# cbass_CBASS_ISC_45820000h register map
Vendor: Texas Instruments
Registers are 32-bit, read-write, reset 0x0 unless marked. A register's access mark holds for its fields unless they carry their own. Offsets are as the file gives them; [hi:lo] are bit positions; {n}, {i} and the like mark numbered series; 'fields as' and 'values as' point back to an identical list.

## cbass_isc (part 2 of 2)
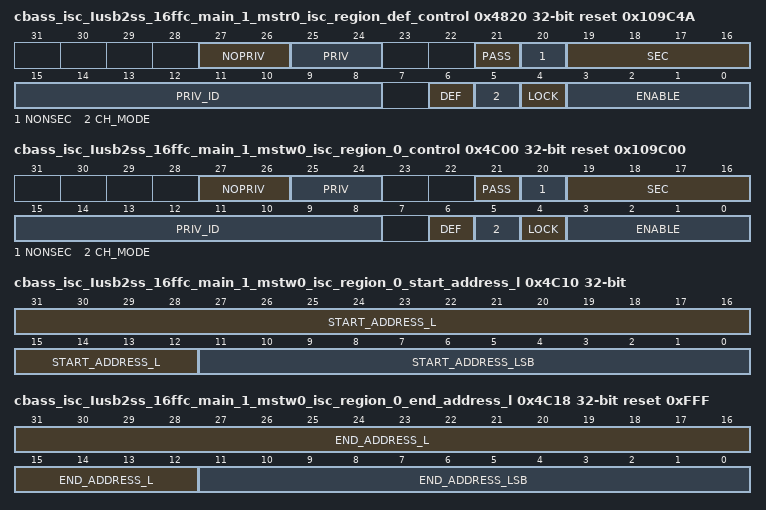
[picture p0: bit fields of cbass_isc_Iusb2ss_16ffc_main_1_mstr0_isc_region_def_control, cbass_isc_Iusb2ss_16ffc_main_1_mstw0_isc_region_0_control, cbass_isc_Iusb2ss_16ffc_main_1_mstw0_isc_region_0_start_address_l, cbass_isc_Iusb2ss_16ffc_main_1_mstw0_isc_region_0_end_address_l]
0x4820 cbass_isc_Iusb2ss_16ffc_main_1_mstr0_isc_region_def_control access not given reset 0x109C4A — The ISC Default Region Control Register defines the control fields for the master Iusb2ss_16ffc_main_1.mstr0 region 1 ISC.
  [27:26] NOPRIV rw — Clear output priv attribute. If each bit is set then the outgoing priv bit is cleared, else the bit is unchanged. Do not set both priv and nopriv for the same bit. Reset Source: domain_default_rst_mod_g_rst_n
  [25:24] PRIV rw — Set outgoing priv attribute. If each bit is set then the outgoing priv bit is set, else the bit is unchanged. Do not set both priv and nopriv for the same bit. Reset Source: domain_default_rst_mod_g_rst_n
  [21] PASS rw — No privID replacement. A value of 1 will pass through privid value. A value of 0 will replace privid with priv_id field value. Reset Source: domain_default_rst_mod_g_rst_n
  [20] NONSEC rw — Make outgoing non-secure. A value of 1 forces secure clear, others do nothing. Do not set both sec and nonsec. Reset Source: domain_default_rst_mod_g_rst_n
  [19:16] SEC rw — Make outgoing secure. A value of 0xA forces secure set, others do nothing. Do not set both sec and nonsec. Reset Source: domain_default_rst_mod_g_rst_n
  [15:8] PRIV_ID rw — Priv ID value to use if pass is 0. Reset Source: domain_default_rst_mod_g_rst_n
  [6] DEF ro — Default region indication. The default region is used when all other regions do not match. Reset Source: domain_default_rst_mod_g_rst_n
  [5] CH_MODE ro — Enable channel mode to match region to a chanid value. Otherwise use address mode to match region to an address range. Reset Source: domain_default_rst_mod_g_rst_n
  [4] LOCK — Lock region. Once set, the region values cannot be modified. Reset Source: domain_default_rst_mod_g_rst_n (access R/W1TS)
  [3:0] ENABLE ro — Enable region. A value of 0xA enables, others disable. Reset Source: domain_default_rst_mod_g_rst_n
0x4C00 cbass_isc_Iusb2ss_16ffc_main_1_mstw0_isc_region_0_control access not given reset 0x109C00 — The ISC Region 0 Control Register defines the control fields for the master Iusb2ss_16ffc_main_1.mstw0 region 0 ISC.
  [27:26] NOPRIV rw — Clear output priv attribute. If each bit is set then the outgoing priv bit is cleared. Reset Source: domain_default_rst_mod_g_rst_n
  [25:24] PRIV rw — Set outgoing priv attribute. If each bit is set then the outgoing priv bit is set. Reset Source: domain_default_rst_mod_g_rst_n
  [21] PASS rw — No privID replacement, pass through value. Reset Source: domain_default_rst_mod_g_rst_n
  [20] NONSEC rw — Make outgoing non-secure. Reset Source: domain_default_rst_mod_g_rst_n
  [19:16] SEC rw — Make outgoing secure. A value of 0xA enables, others disable. Reset Source: domain_default_rst_mod_g_rst_n
  [15:8] PRIV_ID rw — Priv ID. Reset Source: domain_default_rst_mod_g_rst_n
  [6] DEF ro — Default region indication. The default region is used when all other regions do not match. Reset Source: domain_default_rst_mod_g_rst_n
  [5] CH_MODE rw — Enable channel mode to match region to a chanid value. Otherwise use address mode to match region to an address range. Reset Source: domain_default_rst_mod_g_rst_n
  [4] LOCK — Lock region. Once set the region values cannot be modified. Reset Source: domain_default_rst_mod_g_rst_n (access R/W1TS)
  [3:0] ENABLE rw — Enable region. A value of 0xA enables, others disable. Reset Source: domain_default_rst_mod_g_rst_n
0x4C10 cbass_isc_Iusb2ss_16ffc_main_1_mstw0_isc_region_0_start_address_l — The ISC Region 0 Start Address Low Register defines the start address bits 31 to 0 for the master Iusb2ss_16ffc_main_1.mstw0 region 0 ISC.
  [31:12] START_ADDRESS_L — Start address bits 31 to 12. Reset Source: domain_default_rst_mod_g_rst_n
  [11:0] START_ADDRESS_LSB — Start address bits 11 to 0 must be 0 as address must be 4KB aligned in address mode. Can also be channel number in channel mode. Reset Source: domain_default_rst_mod_g_rst_n
0x4C14 cbass_isc_Iusb2ss_16ffc_main_1_mstw0_isc_region_0_start_address_h — The ISC Region 0 Start Address High Register defines the start address bits 47 to 32 for the master Iusb2ss_16ffc_main_1.mstw0 region 0 ISC.
  [15:0] START_ADDRESS_H — Start address bits 47 to 32. Reset Source: domain_default_rst_mod_g_rst_n
0x4C18 cbass_isc_Iusb2ss_16ffc_main_1_mstw0_isc_region_0_end_address_l access per field reset 0xFFF — The ISC Region 0 End Address Low Register defines the end included address bits 31 to 0 for the master Iusb2ss_16ffc_main_1.mstw0 region 0 ISC.
  [31:12] END_ADDRESS_L rw — End address bits 31 to 12 to include in the match. Reset Source: domain_default_rst_mod_g_rst_n
  [11:0] END_ADDRESS_LSB ro — End address bits 11 to 0 are forced to Fs as address must be 4KB aligned. Reset Source: domain_default_rst_mod_g_rst_n
0x4C1C cbass_isc_Iusb2ss_16ffc_main_1_mstw0_isc_region_0_end_address_h — The ISC Region 0 End Address High Register defines the end address bits 47 to 32 for the master Iusb2ss_16ffc_main_1.mstw0 region 0 ISC.
  [15:0] END_ADDRESS_H — End address bits 47 to 32. Reset Source: domain_default_rst_mod_g_rst_n
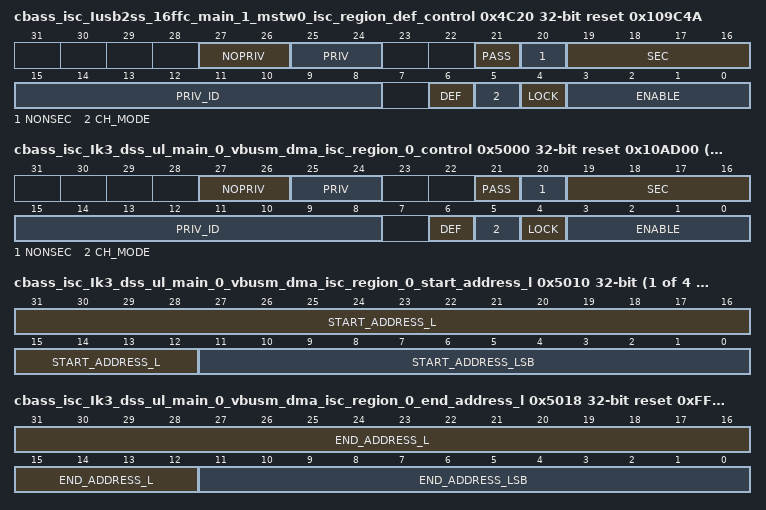
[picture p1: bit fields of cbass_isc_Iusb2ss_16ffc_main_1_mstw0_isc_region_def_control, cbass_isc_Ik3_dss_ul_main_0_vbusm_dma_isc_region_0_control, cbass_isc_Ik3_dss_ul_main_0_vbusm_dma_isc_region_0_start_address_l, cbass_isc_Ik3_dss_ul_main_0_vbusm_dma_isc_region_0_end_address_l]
0x4C20 cbass_isc_Iusb2ss_16ffc_main_1_mstw0_isc_region_def_control access not given reset 0x109C4A — The ISC Default Region Control Register defines the control fields for the master Iusb2ss_16ffc_main_1.mstw0 region 1 ISC.
  fields as cbass_isc_Iusb2ss_16ffc_main_1_mstr0_isc_region_def_control
{0x5000+0x20*i} cbass_isc_Ik3_dss_ul_main_0_vbusm_dma_isc_region_{i}_control access not given reset 0x10AD00 (i=0..3) — The ISC Region {i} Control Register defines the control fields for the master Ik3_dss_ul_main_0.vbusm_dma region {i} ISC.
  fields as cbass_isc_Iusb2ss_16ffc_main_1_mstw0_isc_region_0_control
{0x5010+0x20*i} cbass_isc_Ik3_dss_ul_main_0_vbusm_dma_isc_region_{i}_start_address_l (i=0..3) — The ISC Region {i} Start Address Low Register defines the start address bits 31 to 0 for the master Ik3_dss_ul_main_0.vbusm_dma region {i} ISC.
  fields as cbass_isc_Iusb2ss_16ffc_main_1_mstw0_isc_region_0_start_address_l
{0x5014+0x20*i} cbass_isc_Ik3_dss_ul_main_0_vbusm_dma_isc_region_{i}_start_address_h (i=0..3) — The ISC Region {i} Start Address High Register defines the start address bits 47 to 32 for the master Ik3_dss_ul_main_0.vbusm_dma region {i} ISC.
  fields as cbass_isc_Iusb2ss_16ffc_main_1_mstw0_isc_region_0_start_address_h
{0x5018+0x20*i} cbass_isc_Ik3_dss_ul_main_0_vbusm_dma_isc_region_{i}_end_address_l access per field reset 0xFFF (i=0..3) — The ISC Region {i} End Address Low Register defines the end included address bits 31 to 0 for the master Ik3_dss_ul_main_0.vbusm_dma region {i} ISC.
  fields as cbass_isc_Iusb2ss_16ffc_main_1_mstw0_isc_region_0_end_address_l
{0x501C+0x20*i} cbass_isc_Ik3_dss_ul_main_0_vbusm_dma_isc_region_{i}_end_address_h (i=0..3) — The ISC Region {i} End Address High Register defines the end address bits 47 to 32 for the master Ik3_dss_ul_main_0.vbusm_dma region {i} ISC.
  fields as cbass_isc_Iusb2ss_16ffc_main_1_mstw0_isc_region_0_end_address_h
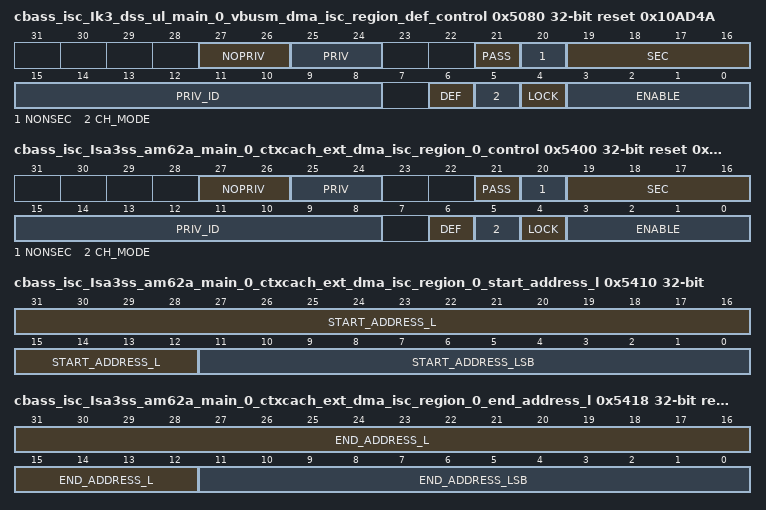
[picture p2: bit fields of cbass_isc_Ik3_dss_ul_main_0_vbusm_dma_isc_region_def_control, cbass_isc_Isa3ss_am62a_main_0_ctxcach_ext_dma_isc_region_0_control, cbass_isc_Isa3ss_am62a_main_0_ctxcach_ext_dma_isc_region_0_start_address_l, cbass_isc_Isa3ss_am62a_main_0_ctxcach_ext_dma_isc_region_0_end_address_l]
0x5080 cbass_isc_Ik3_dss_ul_main_0_vbusm_dma_isc_region_def_control access not given reset 0x10AD4A — The ISC Default Region Control Register defines the control fields for the master Ik3_dss_ul_main_0.vbusm_dma region 4 ISC.
  fields as cbass_isc_Iusb2ss_16ffc_main_1_mstr0_isc_region_def_control
0x5400 cbass_isc_Isa3ss_am62a_main_0_ctxcach_ext_dma_isc_region_0_control access not given reset 0x109800 — The ISC Region 0 Control Register defines the control fields for the master Isa3ss_am62a_main_0.ctxcach_ext_dma region 0 ISC.
  fields as cbass_isc_Iusb2ss_16ffc_main_1_mstw0_isc_region_0_control
0x5410 cbass_isc_Isa3ss_am62a_main_0_ctxcach_ext_dma_isc_region_0_start_address_l — The ISC Region 0 Start Address Low Register defines the start address bits 31 to 0 for the master Isa3ss_am62a_main_0.ctxcach_ext_dma region 0 ISC.
  fields as cbass_isc_Iusb2ss_16ffc_main_1_mstw0_isc_region_0_start_address_l
0x5414 cbass_isc_Isa3ss_am62a_main_0_ctxcach_ext_dma_isc_region_0_start_address_h — The ISC Region 0 Start Address High Register defines the start address bits 47 to 32 for the master Isa3ss_am62a_main_0.ctxcach_ext_dma region 0 ISC.
  fields as cbass_isc_Iusb2ss_16ffc_main_1_mstw0_isc_region_0_start_address_h
0x5418 cbass_isc_Isa3ss_am62a_main_0_ctxcach_ext_dma_isc_region_0_end_address_l access per field reset 0xFFF — The ISC Region 0 End Address Low Register defines the end included address bits 31 to 0 for the master Isa3ss_am62a_main_0.ctxcach_ext_dma region 0 ISC.
  fields as cbass_isc_Iusb2ss_16ffc_main_1_mstw0_isc_region_0_end_address_l
0x541C cbass_isc_Isa3ss_am62a_main_0_ctxcach_ext_dma_isc_region_0_end_address_h — The ISC Region 0 End Address High Register defines the end address bits 47 to 32 for the master Isa3ss_am62a_main_0.ctxcach_ext_dma region 0 ISC.
  fields as cbass_isc_Iusb2ss_16ffc_main_1_mstw0_isc_region_0_end_address_h
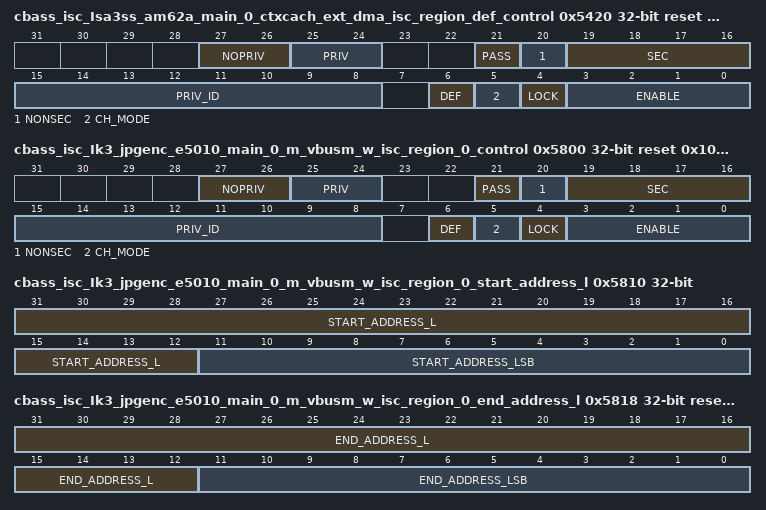
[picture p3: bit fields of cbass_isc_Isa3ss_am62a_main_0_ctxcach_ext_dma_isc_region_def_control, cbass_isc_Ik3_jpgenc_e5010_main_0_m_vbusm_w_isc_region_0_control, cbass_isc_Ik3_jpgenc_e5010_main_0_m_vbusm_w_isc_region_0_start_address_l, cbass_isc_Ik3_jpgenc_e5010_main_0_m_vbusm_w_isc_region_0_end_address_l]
0x5420 cbass_isc_Isa3ss_am62a_main_0_ctxcach_ext_dma_isc_region_def_control access not given reset 0x10984A — The ISC Default Region Control Register defines the control fields for the master Isa3ss_am62a_main_0.ctxcach_ext_dma region 1 ISC.
  fields as cbass_isc_Iusb2ss_16ffc_main_1_mstr0_isc_region_def_control
0x5800 cbass_isc_Ik3_jpgenc_e5010_main_0_m_vbusm_w_isc_region_0_control access not given reset 0x10BE00 — The ISC Region 0 Control Register defines the control fields for the master Ik3_jpgenc_e5010_main_0.m_vbusm_w region 0 ISC.
  fields as cbass_isc_Iusb2ss_16ffc_main_1_mstw0_isc_region_0_control
0x5810 cbass_isc_Ik3_jpgenc_e5010_main_0_m_vbusm_w_isc_region_0_start_address_l — The ISC Region 0 Start Address Low Register defines the start address bits 31 to 0 for the master Ik3_jpgenc_e5010_main_0.m_vbusm_w region 0 ISC.
  fields as cbass_isc_Iusb2ss_16ffc_main_1_mstw0_isc_region_0_start_address_l
0x5814 cbass_isc_Ik3_jpgenc_e5010_main_0_m_vbusm_w_isc_region_0_start_address_h — The ISC Region 0 Start Address High Register defines the start address bits 47 to 32 for the master Ik3_jpgenc_e5010_main_0.m_vbusm_w region 0 ISC.
  fields as cbass_isc_Iusb2ss_16ffc_main_1_mstw0_isc_region_0_start_address_h
0x5818 cbass_isc_Ik3_jpgenc_e5010_main_0_m_vbusm_w_isc_region_0_end_address_l access per field reset 0xFFF — The ISC Region 0 End Address Low Register defines the end included address bits 31 to 0 for the master Ik3_jpgenc_e5010_main_0.m_vbusm_w region 0 ISC.
  fields as cbass_isc_Iusb2ss_16ffc_main_1_mstw0_isc_region_0_end_address_l
0x581C cbass_isc_Ik3_jpgenc_e5010_main_0_m_vbusm_w_isc_region_0_end_address_h — The ISC Region 0 End Address High Register defines the end address bits 47 to 32 for the master Ik3_jpgenc_e5010_main_0.m_vbusm_w region 0 ISC.
  fields as cbass_isc_Iusb2ss_16ffc_main_1_mstw0_isc_region_0_end_address_h
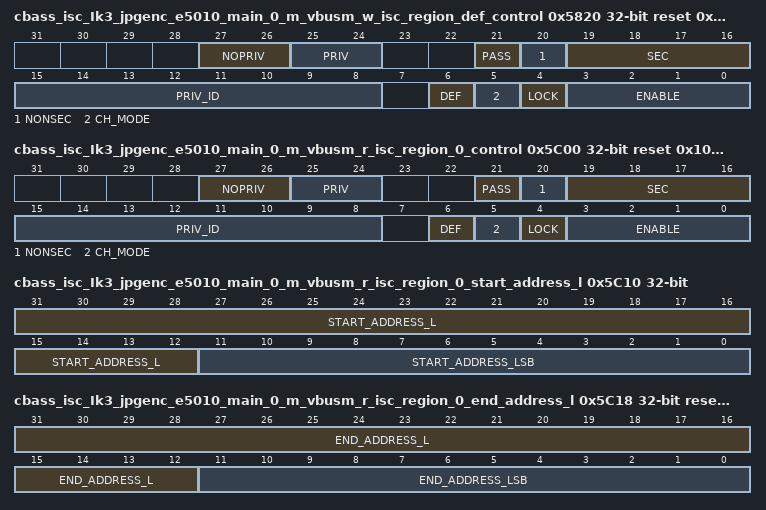
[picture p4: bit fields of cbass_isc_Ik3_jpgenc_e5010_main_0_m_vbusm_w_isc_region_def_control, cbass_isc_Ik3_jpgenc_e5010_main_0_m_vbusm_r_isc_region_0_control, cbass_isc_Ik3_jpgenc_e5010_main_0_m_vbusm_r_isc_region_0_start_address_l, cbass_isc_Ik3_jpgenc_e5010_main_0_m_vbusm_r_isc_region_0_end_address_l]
0x5820 cbass_isc_Ik3_jpgenc_e5010_main_0_m_vbusm_w_isc_region_def_control access not given reset 0x10BE4A — The ISC Default Region Control Register defines the control fields for the master Ik3_jpgenc_e5010_main_0.m_vbusm_w region 1 ISC.
  fields as cbass_isc_Iusb2ss_16ffc_main_1_mstr0_isc_region_def_control
0x5C00 cbass_isc_Ik3_jpgenc_e5010_main_0_m_vbusm_r_isc_region_0_control access not given reset 0x10BE00 — The ISC Region 0 Control Register defines the control fields for the master Ik3_jpgenc_e5010_main_0.m_vbusm_r region 0 ISC.
  fields as cbass_isc_Iusb2ss_16ffc_main_1_mstw0_isc_region_0_control
0x5C10 cbass_isc_Ik3_jpgenc_e5010_main_0_m_vbusm_r_isc_region_0_start_address_l — The ISC Region 0 Start Address Low Register defines the start address bits 31 to 0 for the master Ik3_jpgenc_e5010_main_0.m_vbusm_r region 0 ISC.
  fields as cbass_isc_Iusb2ss_16ffc_main_1_mstw0_isc_region_0_start_address_l
0x5C14 cbass_isc_Ik3_jpgenc_e5010_main_0_m_vbusm_r_isc_region_0_start_address_h — The ISC Region 0 Start Address High Register defines the start address bits 47 to 32 for the master Ik3_jpgenc_e5010_main_0.m_vbusm_r region 0 ISC.
  fields as cbass_isc_Iusb2ss_16ffc_main_1_mstw0_isc_region_0_start_address_h
0x5C18 cbass_isc_Ik3_jpgenc_e5010_main_0_m_vbusm_r_isc_region_0_end_address_l access per field reset 0xFFF — The ISC Region 0 End Address Low Register defines the end included address bits 31 to 0 for the master Ik3_jpgenc_e5010_main_0.m_vbusm_r region 0 ISC.
  fields as cbass_isc_Iusb2ss_16ffc_main_1_mstw0_isc_region_0_end_address_l
0x5C1C cbass_isc_Ik3_jpgenc_e5010_main_0_m_vbusm_r_isc_region_0_end_address_h — The ISC Region 0 End Address High Register defines the end address bits 47 to 32 for the master Ik3_jpgenc_e5010_main_0.m_vbusm_r region 0 ISC.
  fields as cbass_isc_Iusb2ss_16ffc_main_1_mstw0_isc_region_0_end_address_h
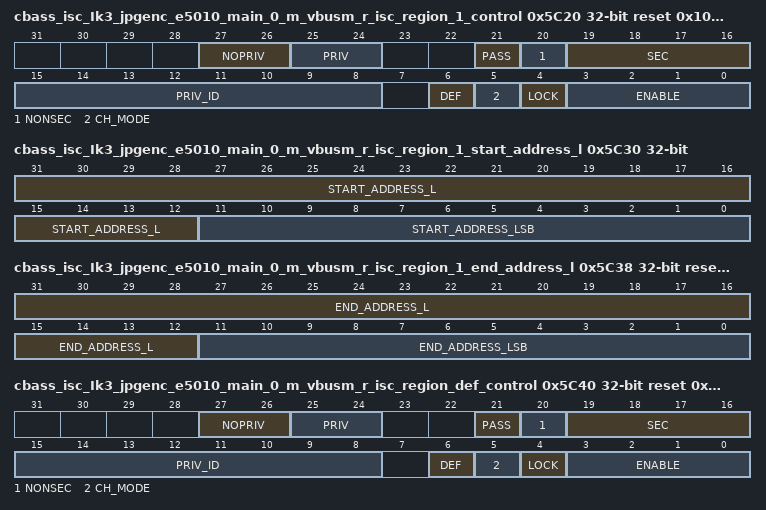
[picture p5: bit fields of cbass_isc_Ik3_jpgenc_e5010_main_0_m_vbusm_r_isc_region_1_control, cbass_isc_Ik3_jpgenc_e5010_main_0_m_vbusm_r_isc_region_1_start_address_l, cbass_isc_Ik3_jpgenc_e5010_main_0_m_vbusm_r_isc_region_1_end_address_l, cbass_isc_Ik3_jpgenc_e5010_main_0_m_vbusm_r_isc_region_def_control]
0x5C20 cbass_isc_Ik3_jpgenc_e5010_main_0_m_vbusm_r_isc_region_1_control access not given reset 0x10BE00 — The ISC Region 1 Control Register defines the control fields for the master Ik3_jpgenc_e5010_main_0.m_vbusm_r region 1 ISC.
  fields as cbass_isc_Iusb2ss_16ffc_main_1_mstw0_isc_region_0_control
0x5C30 cbass_isc_Ik3_jpgenc_e5010_main_0_m_vbusm_r_isc_region_1_start_address_l — The ISC Region 1 Start Address Low Register defines the start address bits 31 to 0 for the master Ik3_jpgenc_e5010_main_0.m_vbusm_r region 1 ISC.
  fields as cbass_isc_Iusb2ss_16ffc_main_1_mstw0_isc_region_0_start_address_l
0x5C34 cbass_isc_Ik3_jpgenc_e5010_main_0_m_vbusm_r_isc_region_1_start_address_h — The ISC Region 1 Start Address High Register defines the start address bits 47 to 32 for the master Ik3_jpgenc_e5010_main_0.m_vbusm_r region 1 ISC.
  fields as cbass_isc_Iusb2ss_16ffc_main_1_mstw0_isc_region_0_start_address_h
0x5C38 cbass_isc_Ik3_jpgenc_e5010_main_0_m_vbusm_r_isc_region_1_end_address_l access per field reset 0xFFF — The ISC Region 1 End Address Low Register defines the end included address bits 31 to 0 for the master Ik3_jpgenc_e5010_main_0.m_vbusm_r region 1 ISC.
  fields as cbass_isc_Iusb2ss_16ffc_main_1_mstw0_isc_region_0_end_address_l
0x5C3C cbass_isc_Ik3_jpgenc_e5010_main_0_m_vbusm_r_isc_region_1_end_address_h — The ISC Region 1 End Address High Register defines the end address bits 47 to 32 for the master Ik3_jpgenc_e5010_main_0.m_vbusm_r region 1 ISC.
  fields as cbass_isc_Iusb2ss_16ffc_main_1_mstw0_isc_region_0_end_address_h
0x5C40 cbass_isc_Ik3_jpgenc_e5010_main_0_m_vbusm_r_isc_region_def_control access not given reset 0x10BE4A — The ISC Default Region Control Register defines the control fields for the master Ik3_jpgenc_e5010_main_0.m_vbusm_r region 2 ISC.
  fields as cbass_isc_Iusb2ss_16ffc_main_1_mstr0_isc_region_def_control
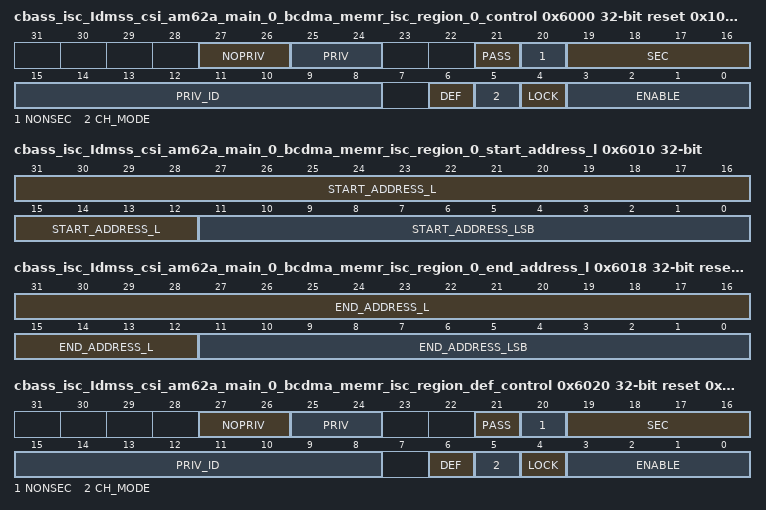
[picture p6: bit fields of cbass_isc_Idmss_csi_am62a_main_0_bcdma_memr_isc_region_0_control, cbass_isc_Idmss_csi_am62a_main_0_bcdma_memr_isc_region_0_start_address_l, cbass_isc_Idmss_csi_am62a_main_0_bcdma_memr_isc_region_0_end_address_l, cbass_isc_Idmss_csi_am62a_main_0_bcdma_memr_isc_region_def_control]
0x6000 cbass_isc_Idmss_csi_am62a_main_0_bcdma_memr_isc_region_0_control access not given reset 0x106500 — The ISC Region 0 Control Register defines the control fields for the master Idmss_csi_am62a_main_0.bcdma_memr region 0 ISC.
  fields as cbass_isc_Iusb2ss_16ffc_main_1_mstw0_isc_region_0_control
0x6010 cbass_isc_Idmss_csi_am62a_main_0_bcdma_memr_isc_region_0_start_address_l — The ISC Region 0 Start Address Low Register defines the start address bits 31 to 0 for the master Idmss_csi_am62a_main_0.bcdma_memr region 0 ISC.
  fields as cbass_isc_Iusb2ss_16ffc_main_1_mstw0_isc_region_0_start_address_l
0x6014 cbass_isc_Idmss_csi_am62a_main_0_bcdma_memr_isc_region_0_start_address_h — The ISC Region 0 Start Address High Register defines the start address bits 47 to 32 for the master Idmss_csi_am62a_main_0.bcdma_memr region 0 ISC.
  fields as cbass_isc_Iusb2ss_16ffc_main_1_mstw0_isc_region_0_start_address_h
0x6018 cbass_isc_Idmss_csi_am62a_main_0_bcdma_memr_isc_region_0_end_address_l access per field reset 0xFFF — The ISC Region 0 End Address Low Register defines the end included address bits 31 to 0 for the master Idmss_csi_am62a_main_0.bcdma_memr region 0 ISC.
  fields as cbass_isc_Iusb2ss_16ffc_main_1_mstw0_isc_region_0_end_address_l
0x601C cbass_isc_Idmss_csi_am62a_main_0_bcdma_memr_isc_region_0_end_address_h — The ISC Region 0 End Address High Register defines the end address bits 47 to 32 for the master Idmss_csi_am62a_main_0.bcdma_memr region 0 ISC.
  fields as cbass_isc_Iusb2ss_16ffc_main_1_mstw0_isc_region_0_end_address_h
0x6020 cbass_isc_Idmss_csi_am62a_main_0_bcdma_memr_isc_region_def_control access not given reset 0x10654A — The ISC Default Region Control Register defines the control fields for the master Idmss_csi_am62a_main_0.bcdma_memr region 1 ISC.
  fields as cbass_isc_Iusb2ss_16ffc_main_1_mstr0_isc_region_def_control
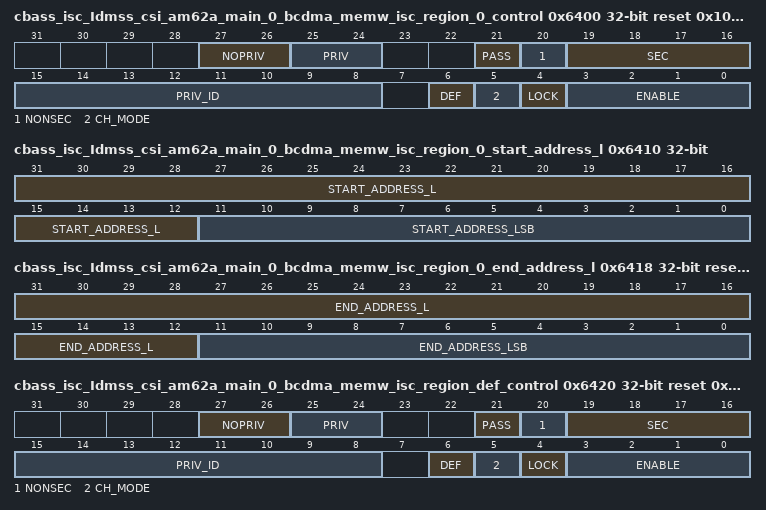
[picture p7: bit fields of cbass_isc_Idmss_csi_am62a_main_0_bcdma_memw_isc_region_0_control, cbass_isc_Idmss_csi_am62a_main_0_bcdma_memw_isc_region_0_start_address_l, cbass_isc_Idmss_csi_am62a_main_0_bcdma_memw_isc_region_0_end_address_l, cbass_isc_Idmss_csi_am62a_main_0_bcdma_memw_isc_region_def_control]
0x6400 cbass_isc_Idmss_csi_am62a_main_0_bcdma_memw_isc_region_0_control access not given reset 0x106500 — The ISC Region 0 Control Register defines the control fields for the master Idmss_csi_am62a_main_0.bcdma_memw region 0 ISC.
  fields as cbass_isc_Iusb2ss_16ffc_main_1_mstw0_isc_region_0_control
0x6410 cbass_isc_Idmss_csi_am62a_main_0_bcdma_memw_isc_region_0_start_address_l — The ISC Region 0 Start Address Low Register defines the start address bits 31 to 0 for the master Idmss_csi_am62a_main_0.bcdma_memw region 0 ISC.
  fields as cbass_isc_Iusb2ss_16ffc_main_1_mstw0_isc_region_0_start_address_l
0x6414 cbass_isc_Idmss_csi_am62a_main_0_bcdma_memw_isc_region_0_start_address_h — The ISC Region 0 Start Address High Register defines the start address bits 47 to 32 for the master Idmss_csi_am62a_main_0.bcdma_memw region 0 ISC.
  fields as cbass_isc_Iusb2ss_16ffc_main_1_mstw0_isc_region_0_start_address_h
0x6418 cbass_isc_Idmss_csi_am62a_main_0_bcdma_memw_isc_region_0_end_address_l access per field reset 0xFFF — The ISC Region 0 End Address Low Register defines the end included address bits 31 to 0 for the master Idmss_csi_am62a_main_0.bcdma_memw region 0 ISC.
  fields as cbass_isc_Iusb2ss_16ffc_main_1_mstw0_isc_region_0_end_address_l
0x641C cbass_isc_Idmss_csi_am62a_main_0_bcdma_memw_isc_region_0_end_address_h — The ISC Region 0 End Address High Register defines the end address bits 47 to 32 for the master Idmss_csi_am62a_main_0.bcdma_memw region 0 ISC.
  fields as cbass_isc_Iusb2ss_16ffc_main_1_mstw0_isc_region_0_end_address_h
0x6420 cbass_isc_Idmss_csi_am62a_main_0_bcdma_memw_isc_region_def_control access not given reset 0x10654A — The ISC Default Region Control Register defines the control fields for the master Idmss_csi_am62a_main_0.bcdma_memw region 1 ISC.
  fields as cbass_isc_Iusb2ss_16ffc_main_1_mstr0_isc_region_def_control
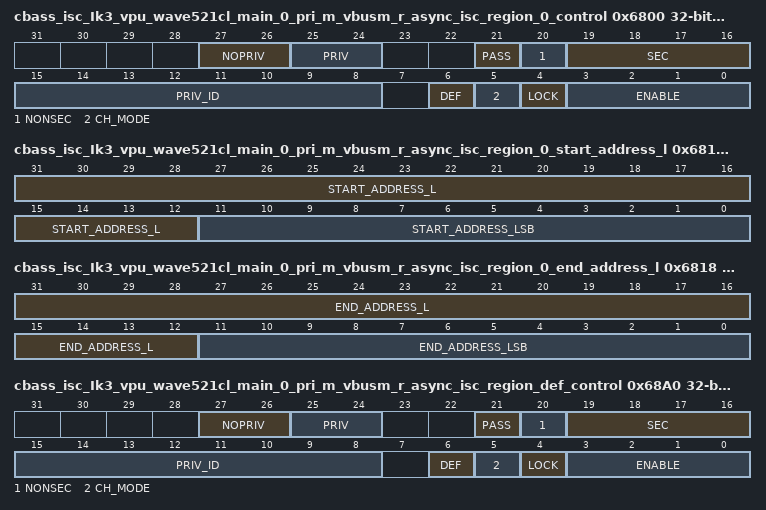
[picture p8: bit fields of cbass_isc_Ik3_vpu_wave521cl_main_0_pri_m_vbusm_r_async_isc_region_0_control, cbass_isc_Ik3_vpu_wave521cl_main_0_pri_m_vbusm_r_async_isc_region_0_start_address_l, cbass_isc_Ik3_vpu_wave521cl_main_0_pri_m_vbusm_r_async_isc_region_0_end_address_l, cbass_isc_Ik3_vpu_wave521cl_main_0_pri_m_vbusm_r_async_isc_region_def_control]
{0x6800+0x20*i} cbass_isc_Ik3_vpu_wave521cl_main_0_pri_m_vbusm_r_async_isc_region_{i}_control access not given reset 0x10BF00 (i=0..4) — The ISC Region {i} Control Register defines the control fields for the master Ik3_vpu_wave521cl_main_0.pri_m_vbusm_r_async region {i} ISC.
  fields as cbass_isc_Iusb2ss_16ffc_main_1_mstw0_isc_region_0_control
{0x6810+0x20*i} cbass_isc_Ik3_vpu_wave521cl_main_0_pri_m_vbusm_r_async_isc_region_{i}_start_address_l (i=0..4) — The ISC Region {i} Start Address Low Register defines the start address bits 31 to 0 for the master Ik3_vpu_wave521cl_main_0.pri_m_vbusm_r_async region {i} ISC.
  fields as cbass_isc_Iusb2ss_16ffc_main_1_mstw0_isc_region_0_start_address_l
{0x6814+0x20*i} cbass_isc_Ik3_vpu_wave521cl_main_0_pri_m_vbusm_r_async_isc_region_{i}_start_address_h (i=0..4) — The ISC Region {i} Start Address High Register defines the start address bits 47 to 32 for the master Ik3_vpu_wave521cl_main_0.pri_m_vbusm_r_async region {i} ISC.
  fields as cbass_isc_Iusb2ss_16ffc_main_1_mstw0_isc_region_0_start_address_h
{0x6818+0x20*i} cbass_isc_Ik3_vpu_wave521cl_main_0_pri_m_vbusm_r_async_isc_region_{i}_end_address_l access per field reset 0xFFF (i=0..4) — The ISC Region {i} End Address Low Register defines the end included address bits 31 to 0 for the master Ik3_vpu_wave521cl_main_0.pri_m_vbusm_r_async region {i} ISC.
  fields as cbass_isc_Iusb2ss_16ffc_main_1_mstw0_isc_region_0_end_address_l
{0x681C+0x20*i} cbass_isc_Ik3_vpu_wave521cl_main_0_pri_m_vbusm_r_async_isc_region_{i}_end_address_h (i=0..4) — The ISC Region {i} End Address High Register defines the end address bits 47 to 32 for the master Ik3_vpu_wave521cl_main_0.pri_m_vbusm_r_async region {i} ISC.
  fields as cbass_isc_Iusb2ss_16ffc_main_1_mstw0_isc_region_0_end_address_h
0x68A0 cbass_isc_Ik3_vpu_wave521cl_main_0_pri_m_vbusm_r_async_isc_region_def_control access not given reset 0x10BF4A — The ISC Default Region Control Register defines the control fields for the master Ik3_vpu_wave521cl_main_0.pri_m_vbusm_r_async region 5 ISC.
  fields as cbass_isc_Iusb2ss_16ffc_main_1_mstr0_isc_region_def_control
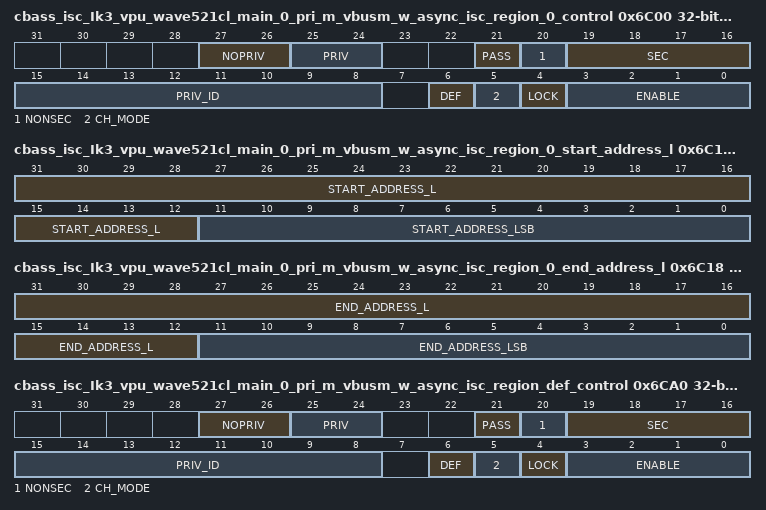
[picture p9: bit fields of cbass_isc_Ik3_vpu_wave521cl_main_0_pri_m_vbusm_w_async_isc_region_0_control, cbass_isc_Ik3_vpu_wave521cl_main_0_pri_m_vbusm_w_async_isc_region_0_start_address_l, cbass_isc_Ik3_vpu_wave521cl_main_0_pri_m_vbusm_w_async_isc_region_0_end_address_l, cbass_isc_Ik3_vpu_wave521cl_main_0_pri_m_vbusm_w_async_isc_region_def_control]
{0x6C00+0x20*i} cbass_isc_Ik3_vpu_wave521cl_main_0_pri_m_vbusm_w_async_isc_region_{i}_control access not given reset 0x10BF00 (i=0..4) — The ISC Region {i} Control Register defines the control fields for the master Ik3_vpu_wave521cl_main_0.pri_m_vbusm_w_async region {i} ISC.
  fields as cbass_isc_Iusb2ss_16ffc_main_1_mstw0_isc_region_0_control
{0x6C10+0x20*i} cbass_isc_Ik3_vpu_wave521cl_main_0_pri_m_vbusm_w_async_isc_region_{i}_start_address_l (i=0..4) — The ISC Region {i} Start Address Low Register defines the start address bits 31 to 0 for the master Ik3_vpu_wave521cl_main_0.pri_m_vbusm_w_async region {i} ISC.
  fields as cbass_isc_Iusb2ss_16ffc_main_1_mstw0_isc_region_0_start_address_l
{0x6C14+0x20*i} cbass_isc_Ik3_vpu_wave521cl_main_0_pri_m_vbusm_w_async_isc_region_{i}_start_address_h (i=0..4) — The ISC Region {i} Start Address High Register defines the start address bits 47 to 32 for the master Ik3_vpu_wave521cl_main_0.pri_m_vbusm_w_async region {i} ISC.
  fields as cbass_isc_Iusb2ss_16ffc_main_1_mstw0_isc_region_0_start_address_h
{0x6C18+0x20*i} cbass_isc_Ik3_vpu_wave521cl_main_0_pri_m_vbusm_w_async_isc_region_{i}_end_address_l access per field reset 0xFFF (i=0..4) — The ISC Region {i} End Address Low Register defines the end included address bits 31 to 0 for the master Ik3_vpu_wave521cl_main_0.pri_m_vbusm_w_async region {i} ISC.
  fields as cbass_isc_Iusb2ss_16ffc_main_1_mstw0_isc_region_0_end_address_l
{0x6C1C+0x20*i} cbass_isc_Ik3_vpu_wave521cl_main_0_pri_m_vbusm_w_async_isc_region_{i}_end_address_h (i=0..4) — The ISC Region {i} End Address High Register defines the end address bits 47 to 32 for the master Ik3_vpu_wave521cl_main_0.pri_m_vbusm_w_async region {i} ISC.
  fields as cbass_isc_Iusb2ss_16ffc_main_1_mstw0_isc_region_0_end_address_h
0x6CA0 cbass_isc_Ik3_vpu_wave521cl_main_0_pri_m_vbusm_w_async_isc_region_def_control access not given reset 0x10BF4A — The ISC Default Region Control Register defines the control fields for the master Ik3_vpu_wave521cl_main_0.pri_m_vbusm_w_async region 5 ISC.
  fields as cbass_isc_Iusb2ss_16ffc_main_1_mstr0_isc_region_def_control
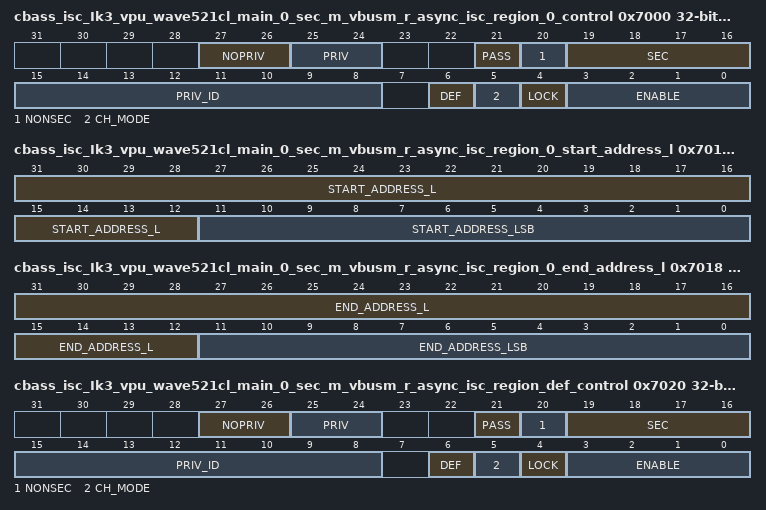
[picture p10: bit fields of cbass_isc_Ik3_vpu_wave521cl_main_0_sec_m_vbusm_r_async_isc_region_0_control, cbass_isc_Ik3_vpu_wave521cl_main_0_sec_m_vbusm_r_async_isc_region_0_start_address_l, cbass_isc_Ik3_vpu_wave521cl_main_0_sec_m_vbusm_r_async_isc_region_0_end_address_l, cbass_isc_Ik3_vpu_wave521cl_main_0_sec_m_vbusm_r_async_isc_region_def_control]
0x7000 cbass_isc_Ik3_vpu_wave521cl_main_0_sec_m_vbusm_r_async_isc_region_0_control access not given reset 0x10BF00 — The ISC Region 0 Control Register defines the control fields for the master Ik3_vpu_wave521cl_main_0.sec_m_vbusm_r_async region 0 ISC.
  fields as cbass_isc_Iusb2ss_16ffc_main_1_mstw0_isc_region_0_control
0x7010 cbass_isc_Ik3_vpu_wave521cl_main_0_sec_m_vbusm_r_async_isc_region_0_start_address_l — The ISC Region 0 Start Address Low Register defines the start address bits 31 to 0 for the master Ik3_vpu_wave521cl_main_0.sec_m_vbusm_r_async region 0 ISC.
  fields as cbass_isc_Iusb2ss_16ffc_main_1_mstw0_isc_region_0_start_address_l
0x7014 cbass_isc_Ik3_vpu_wave521cl_main_0_sec_m_vbusm_r_async_isc_region_0_start_address_h — The ISC Region 0 Start Address High Register defines the start address bits 47 to 32 for the master Ik3_vpu_wave521cl_main_0.sec_m_vbusm_r_async region 0 ISC.
  fields as cbass_isc_Iusb2ss_16ffc_main_1_mstw0_isc_region_0_start_address_h
0x7018 cbass_isc_Ik3_vpu_wave521cl_main_0_sec_m_vbusm_r_async_isc_region_0_end_address_l access per field reset 0xFFF — The ISC Region 0 End Address Low Register defines the end included address bits 31 to 0 for the master Ik3_vpu_wave521cl_main_0.sec_m_vbusm_r_async region 0 ISC.
  fields as cbass_isc_Iusb2ss_16ffc_main_1_mstw0_isc_region_0_end_address_l
0x701C cbass_isc_Ik3_vpu_wave521cl_main_0_sec_m_vbusm_r_async_isc_region_0_end_address_h — The ISC Region 0 End Address High Register defines the end address bits 47 to 32 for the master Ik3_vpu_wave521cl_main_0.sec_m_vbusm_r_async region 0 ISC.
  fields as cbass_isc_Iusb2ss_16ffc_main_1_mstw0_isc_region_0_end_address_h
0x7020 cbass_isc_Ik3_vpu_wave521cl_main_0_sec_m_vbusm_r_async_isc_region_def_control access not given reset 0x10BF4A — The ISC Default Region Control Register defines the control fields for the master Ik3_vpu_wave521cl_main_0.sec_m_vbusm_r_async region 1 ISC.
  fields as cbass_isc_Iusb2ss_16ffc_main_1_mstr0_isc_region_def_control
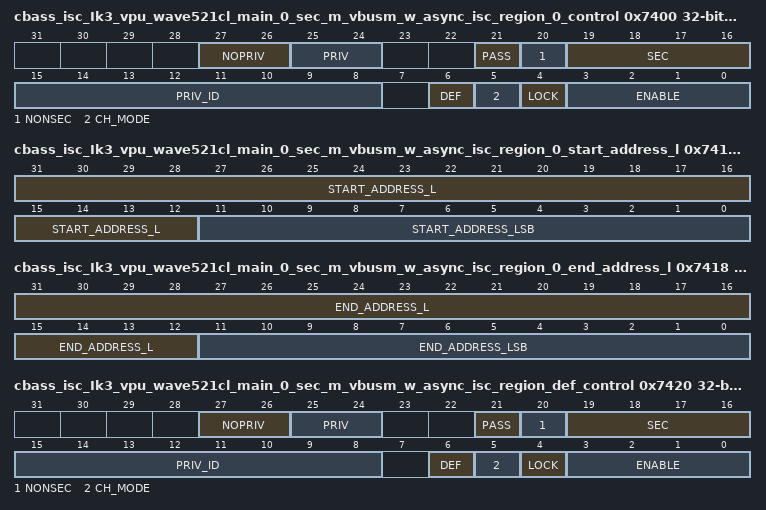
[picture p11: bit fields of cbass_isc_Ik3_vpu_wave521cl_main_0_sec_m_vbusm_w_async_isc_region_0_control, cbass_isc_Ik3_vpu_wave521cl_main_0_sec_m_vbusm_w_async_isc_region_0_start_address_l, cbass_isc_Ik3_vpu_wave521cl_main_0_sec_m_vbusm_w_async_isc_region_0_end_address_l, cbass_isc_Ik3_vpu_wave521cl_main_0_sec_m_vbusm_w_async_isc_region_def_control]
0x7400 cbass_isc_Ik3_vpu_wave521cl_main_0_sec_m_vbusm_w_async_isc_region_0_control access not given reset 0x10BF00 — The ISC Region 0 Control Register defines the control fields for the master Ik3_vpu_wave521cl_main_0.sec_m_vbusm_w_async region 0 ISC.
  fields as cbass_isc_Iusb2ss_16ffc_main_1_mstw0_isc_region_0_control
0x7410 cbass_isc_Ik3_vpu_wave521cl_main_0_sec_m_vbusm_w_async_isc_region_0_start_address_l — The ISC Region 0 Start Address Low Register defines the start address bits 31 to 0 for the master Ik3_vpu_wave521cl_main_0.sec_m_vbusm_w_async region 0 ISC.
  fields as cbass_isc_Iusb2ss_16ffc_main_1_mstw0_isc_region_0_start_address_l
0x7414 cbass_isc_Ik3_vpu_wave521cl_main_0_sec_m_vbusm_w_async_isc_region_0_start_address_h — The ISC Region 0 Start Address High Register defines the start address bits 47 to 32 for the master Ik3_vpu_wave521cl_main_0.sec_m_vbusm_w_async region 0 ISC.
  fields as cbass_isc_Iusb2ss_16ffc_main_1_mstw0_isc_region_0_start_address_h
0x7418 cbass_isc_Ik3_vpu_wave521cl_main_0_sec_m_vbusm_w_async_isc_region_0_end_address_l access per field reset 0xFFF — The ISC Region 0 End Address Low Register defines the end included address bits 31 to 0 for the master Ik3_vpu_wave521cl_main_0.sec_m_vbusm_w_async region 0 ISC.
  fields as cbass_isc_Iusb2ss_16ffc_main_1_mstw0_isc_region_0_end_address_l
0x741C cbass_isc_Ik3_vpu_wave521cl_main_0_sec_m_vbusm_w_async_isc_region_0_end_address_h — The ISC Region 0 End Address High Register defines the end address bits 47 to 32 for the master Ik3_vpu_wave521cl_main_0.sec_m_vbusm_w_async region 0 ISC.
  fields as cbass_isc_Iusb2ss_16ffc_main_1_mstw0_isc_region_0_end_address_h
0x7420 cbass_isc_Ik3_vpu_wave521cl_main_0_sec_m_vbusm_w_async_isc_region_def_control access not given reset 0x10BF4A — The ISC Default Region Control Register defines the control fields for the master Ik3_vpu_wave521cl_main_0.sec_m_vbusm_w_async region 1 ISC.
  fields as cbass_isc_Iusb2ss_16ffc_main_1_mstr0_isc_region_def_control
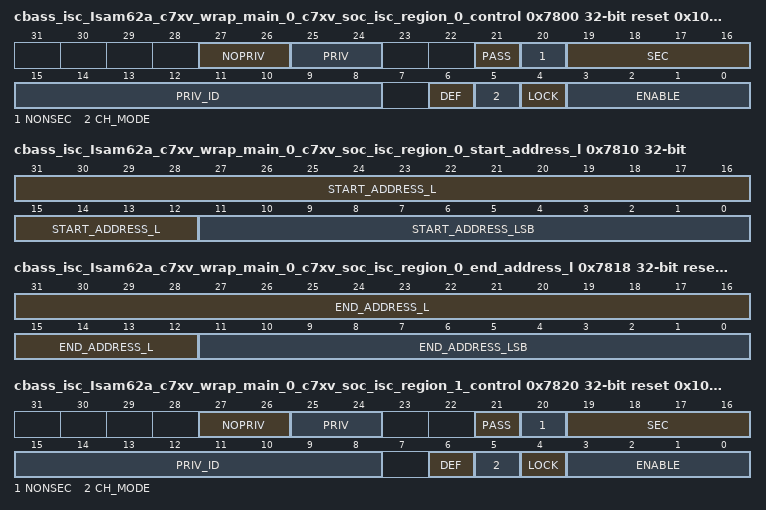
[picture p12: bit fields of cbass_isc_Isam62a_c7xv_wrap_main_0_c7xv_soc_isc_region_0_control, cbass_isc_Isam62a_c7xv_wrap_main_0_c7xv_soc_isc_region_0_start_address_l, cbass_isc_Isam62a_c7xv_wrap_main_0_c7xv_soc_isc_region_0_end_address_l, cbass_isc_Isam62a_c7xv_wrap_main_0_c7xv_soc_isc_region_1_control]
0x7800 cbass_isc_Isam62a_c7xv_wrap_main_0_c7xv_soc_isc_region_0_control access not given reset 0x102000 — The ISC Region 0 Control Register defines the control fields for the master Isam62a_c7xv_wrap_main_0.c7xv_soc region 0 ISC.
  fields as cbass_isc_Iusb2ss_16ffc_main_1_mstw0_isc_region_0_control
0x7810 cbass_isc_Isam62a_c7xv_wrap_main_0_c7xv_soc_isc_region_0_start_address_l — The ISC Region 0 Start Address Low Register defines the start address bits 31 to 0 for the master Isam62a_c7xv_wrap_main_0.c7xv_soc region 0 ISC.
  fields as cbass_isc_Iusb2ss_16ffc_main_1_mstw0_isc_region_0_start_address_l
0x7814 cbass_isc_Isam62a_c7xv_wrap_main_0_c7xv_soc_isc_region_0_start_address_h — The ISC Region 0 Start Address High Register defines the start address bits 47 to 32 for the master Isam62a_c7xv_wrap_main_0.c7xv_soc region 0 ISC.
  fields as cbass_isc_Iusb2ss_16ffc_main_1_mstw0_isc_region_0_start_address_h
0x7818 cbass_isc_Isam62a_c7xv_wrap_main_0_c7xv_soc_isc_region_0_end_address_l access per field reset 0xFFF — The ISC Region 0 End Address Low Register defines the end included address bits 31 to 0 for the master Isam62a_c7xv_wrap_main_0.c7xv_soc region 0 ISC.
  fields as cbass_isc_Iusb2ss_16ffc_main_1_mstw0_isc_region_0_end_address_l
0x781C cbass_isc_Isam62a_c7xv_wrap_main_0_c7xv_soc_isc_region_0_end_address_h — The ISC Region 0 End Address High Register defines the end address bits 47 to 32 for the master Isam62a_c7xv_wrap_main_0.c7xv_soc region 0 ISC.
  fields as cbass_isc_Iusb2ss_16ffc_main_1_mstw0_isc_region_0_end_address_h
0x7820 cbass_isc_Isam62a_c7xv_wrap_main_0_c7xv_soc_isc_region_1_control access not given reset 0x102000 — The ISC Region 1 Control Register defines the control fields for the master Isam62a_c7xv_wrap_main_0.c7xv_soc region 1 ISC.
  fields as cbass_isc_Iusb2ss_16ffc_main_1_mstw0_isc_region_0_control
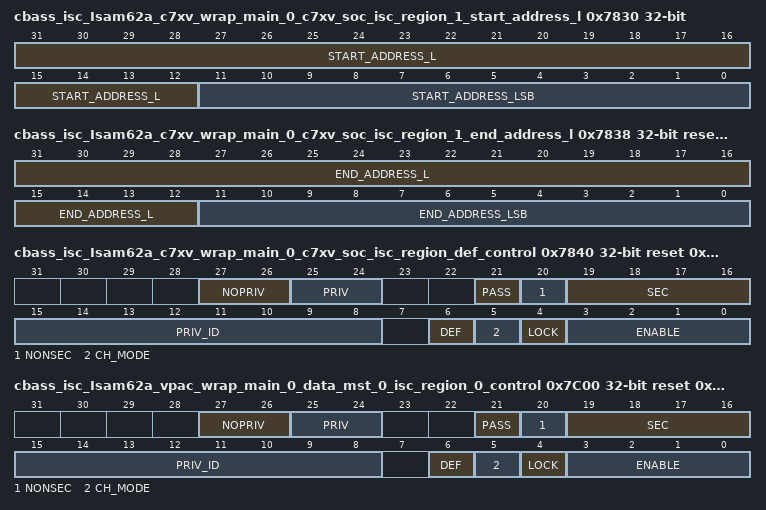
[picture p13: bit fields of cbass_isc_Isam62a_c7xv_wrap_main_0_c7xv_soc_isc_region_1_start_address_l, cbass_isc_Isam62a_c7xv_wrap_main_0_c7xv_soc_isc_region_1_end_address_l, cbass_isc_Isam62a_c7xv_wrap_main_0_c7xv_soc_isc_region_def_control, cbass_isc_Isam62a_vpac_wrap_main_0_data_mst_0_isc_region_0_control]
0x7830 cbass_isc_Isam62a_c7xv_wrap_main_0_c7xv_soc_isc_region_1_start_address_l — The ISC Region 1 Start Address Low Register defines the start address bits 31 to 0 for the master Isam62a_c7xv_wrap_main_0.c7xv_soc region 1 ISC.
  fields as cbass_isc_Iusb2ss_16ffc_main_1_mstw0_isc_region_0_start_address_l
0x7834 cbass_isc_Isam62a_c7xv_wrap_main_0_c7xv_soc_isc_region_1_start_address_h — The ISC Region 1 Start Address High Register defines the start address bits 47 to 32 for the master Isam62a_c7xv_wrap_main_0.c7xv_soc region 1 ISC.
  fields as cbass_isc_Iusb2ss_16ffc_main_1_mstw0_isc_region_0_start_address_h
0x7838 cbass_isc_Isam62a_c7xv_wrap_main_0_c7xv_soc_isc_region_1_end_address_l access per field reset 0xFFF — The ISC Region 1 End Address Low Register defines the end included address bits 31 to 0 for the master Isam62a_c7xv_wrap_main_0.c7xv_soc region 1 ISC.
  fields as cbass_isc_Iusb2ss_16ffc_main_1_mstw0_isc_region_0_end_address_l
0x783C cbass_isc_Isam62a_c7xv_wrap_main_0_c7xv_soc_isc_region_1_end_address_h — The ISC Region 1 End Address High Register defines the end address bits 47 to 32 for the master Isam62a_c7xv_wrap_main_0.c7xv_soc region 1 ISC.
  fields as cbass_isc_Iusb2ss_16ffc_main_1_mstw0_isc_region_0_end_address_h
0x7840 cbass_isc_Isam62a_c7xv_wrap_main_0_c7xv_soc_isc_region_def_control access not given reset 0x10204A — The ISC Default Region Control Register defines the control fields for the master Isam62a_c7xv_wrap_main_0.c7xv_soc region 2 ISC.
  fields as cbass_isc_Iusb2ss_16ffc_main_1_mstr0_isc_region_def_control
0x7C00 cbass_isc_Isam62a_vpac_wrap_main_0_data_mst_0_isc_region_0_control access not given reset 0x106600 — The ISC Region 0 Control Register defines the control fields for the master Isam62a_vpac_wrap_main_0.data_mst_0 region 0 ISC.
  fields as cbass_isc_Iusb2ss_16ffc_main_1_mstw0_isc_region_0_control
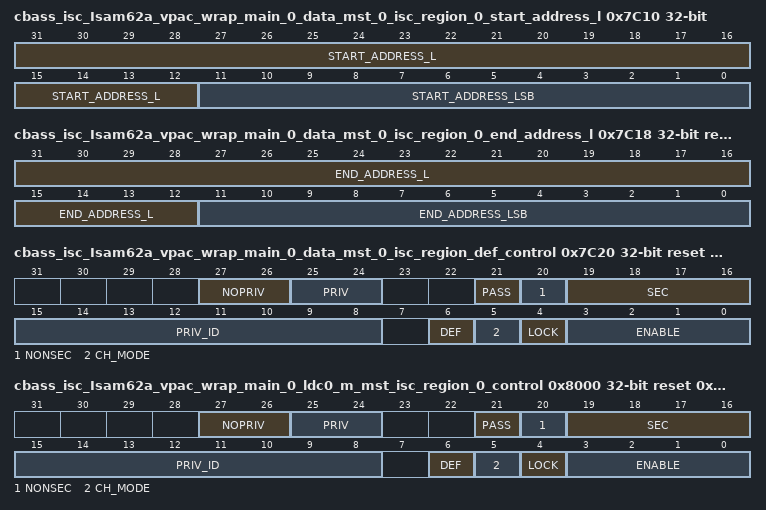
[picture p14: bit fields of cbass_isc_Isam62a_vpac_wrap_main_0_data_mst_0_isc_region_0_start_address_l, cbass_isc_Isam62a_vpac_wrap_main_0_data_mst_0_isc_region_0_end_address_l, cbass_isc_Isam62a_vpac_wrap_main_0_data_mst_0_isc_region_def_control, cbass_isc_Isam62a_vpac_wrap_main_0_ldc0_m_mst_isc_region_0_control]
0x7C10 cbass_isc_Isam62a_vpac_wrap_main_0_data_mst_0_isc_region_0_start_address_l — The ISC Region 0 Start Address Low Register defines the start address bits 31 to 0 for the master Isam62a_vpac_wrap_main_0.data_mst_0 region 0 ISC.
  fields as cbass_isc_Iusb2ss_16ffc_main_1_mstw0_isc_region_0_start_address_l
0x7C14 cbass_isc_Isam62a_vpac_wrap_main_0_data_mst_0_isc_region_0_start_address_h — The ISC Region 0 Start Address High Register defines the start address bits 47 to 32 for the master Isam62a_vpac_wrap_main_0.data_mst_0 region 0 ISC.
  fields as cbass_isc_Iusb2ss_16ffc_main_1_mstw0_isc_region_0_start_address_h
0x7C18 cbass_isc_Isam62a_vpac_wrap_main_0_data_mst_0_isc_region_0_end_address_l access per field reset 0xFFF — The ISC Region 0 End Address Low Register defines the end included address bits 31 to 0 for the master Isam62a_vpac_wrap_main_0.data_mst_0 region 0 ISC.
  fields as cbass_isc_Iusb2ss_16ffc_main_1_mstw0_isc_region_0_end_address_l
0x7C1C cbass_isc_Isam62a_vpac_wrap_main_0_data_mst_0_isc_region_0_end_address_h — The ISC Region 0 End Address High Register defines the end address bits 47 to 32 for the master Isam62a_vpac_wrap_main_0.data_mst_0 region 0 ISC.
  fields as cbass_isc_Iusb2ss_16ffc_main_1_mstw0_isc_region_0_end_address_h
0x7C20 cbass_isc_Isam62a_vpac_wrap_main_0_data_mst_0_isc_region_def_control access not given reset 0x10664A — The ISC Default Region Control Register defines the control fields for the master Isam62a_vpac_wrap_main_0.data_mst_0 region 1 ISC.
  fields as cbass_isc_Iusb2ss_16ffc_main_1_mstr0_isc_region_def_control
0x8000 cbass_isc_Isam62a_vpac_wrap_main_0_ldc0_m_mst_isc_region_0_control access not given reset 0x106800 — The ISC Region 0 Control Register defines the control fields for the master Isam62a_vpac_wrap_main_0.ldc0_m_mst region 0 ISC.
  fields as cbass_isc_Iusb2ss_16ffc_main_1_mstw0_isc_region_0_control
0x8010 cbass_isc_Isam62a_vpac_wrap_main_0_ldc0_m_mst_isc_region_0_start_address_l — The ISC Region 0 Start Address Low Register defines the start address bits 31 to 0 for the master Isam62a_vpac_wrap_main_0.ldc0_m_mst region 0 ISC.
  fields as cbass_isc_Iusb2ss_16ffc_main_1_mstw0_isc_region_0_start_address_l
0x8014 cbass_isc_Isam62a_vpac_wrap_main_0_ldc0_m_mst_isc_region_0_start_address_h — The ISC Region 0 Start Address High Register defines the start address bits 47 to 32 for the master Isam62a_vpac_wrap_main_0.ldc0_m_mst region 0 ISC.
  fields as cbass_isc_Iusb2ss_16ffc_main_1_mstw0_isc_region_0_start_address_h
0x8018 cbass_isc_Isam62a_vpac_wrap_main_0_ldc0_m_mst_isc_region_0_end_address_l access per field reset 0xFFF — The ISC Region 0 End Address Low Register defines the end included address bits 31 to 0 for the master Isam62a_vpac_wrap_main_0.ldc0_m_mst region 0 ISC.
  fields as cbass_isc_Iusb2ss_16ffc_main_1_mstw0_isc_region_0_end_address_l
0x801C cbass_isc_Isam62a_vpac_wrap_main_0_ldc0_m_mst_isc_region_0_end_address_h — The ISC Region 0 End Address High Register defines the end address bits 47 to 32 for the master Isam62a_vpac_wrap_main_0.ldc0_m_mst region 0 ISC.
  fields as cbass_isc_Iusb2ss_16ffc_main_1_mstw0_isc_region_0_end_address_h
0x8020 cbass_isc_Isam62a_vpac_wrap_main_0_ldc0_m_mst_isc_region_def_control access not given reset 0x10684A — The ISC Default Region Control Register defines the control fields for the master Isam62a_vpac_wrap_main_0.ldc0_m_mst region 1 ISC.
  fields as cbass_isc_Iusb2ss_16ffc_main_1_mstr0_isc_region_def_control
0x8400 cbass_isc_Isam62a_vpac_wrap_main_0_data_mst_1_isc_region_0_control access not given reset 0x106700 — The ISC Region 0 Control Register defines the control fields for the master Isam62a_vpac_wrap_main_0.data_mst_1 region 0 ISC.
  fields as cbass_isc_Iusb2ss_16ffc_main_1_mstw0_isc_region_0_control
0x8410 cbass_isc_Isam62a_vpac_wrap_main_0_data_mst_1_isc_region_0_start_address_l — The ISC Region 0 Start Address Low Register defines the start address bits 31 to 0 for the master Isam62a_vpac_wrap_main_0.data_mst_1 region 0 ISC.
  fields as cbass_isc_Iusb2ss_16ffc_main_1_mstw0_isc_region_0_start_address_l
0x8414 cbass_isc_Isam62a_vpac_wrap_main_0_data_mst_1_isc_region_0_start_address_h — The ISC Region 0 Start Address High Register defines the start address bits 47 to 32 for the master Isam62a_vpac_wrap_main_0.data_mst_1 region 0 ISC.
  fields as cbass_isc_Iusb2ss_16ffc_main_1_mstw0_isc_region_0_start_address_h
0x8418 cbass_isc_Isam62a_vpac_wrap_main_0_data_mst_1_isc_region_0_end_address_l access per field reset 0xFFF — The ISC Region 0 End Address Low Register defines the end included address bits 31 to 0 for the master Isam62a_vpac_wrap_main_0.data_mst_1 region 0 ISC.
  fields as cbass_isc_Iusb2ss_16ffc_main_1_mstw0_isc_region_0_end_address_l
0x841C cbass_isc_Isam62a_vpac_wrap_main_0_data_mst_1_isc_region_0_end_address_h — The ISC Region 0 End Address High Register defines the end address bits 47 to 32 for the master Isam62a_vpac_wrap_main_0.data_mst_1 region 0 ISC.
  fields as cbass_isc_Iusb2ss_16ffc_main_1_mstw0_isc_region_0_end_address_h
0x8420 cbass_isc_Isam62a_vpac_wrap_main_0_data_mst_1_isc_region_def_control access not given reset 0x10674A — The ISC Default Region Control Register defines the control fields for the master Isam62a_vpac_wrap_main_0.data_mst_1 region 1 ISC.
  fields as cbass_isc_Iusb2ss_16ffc_main_1_mstr0_isc_region_def_control
